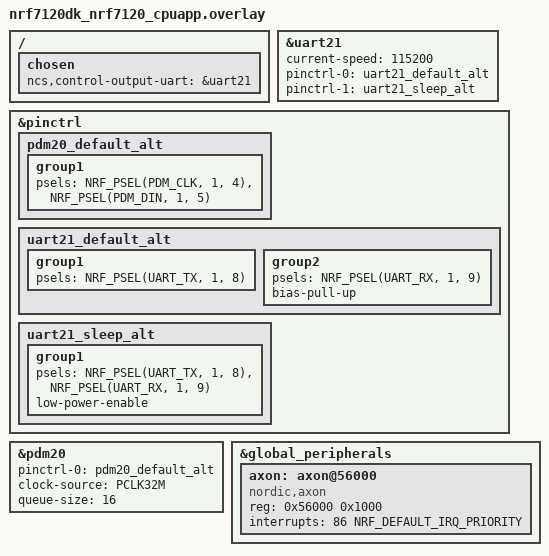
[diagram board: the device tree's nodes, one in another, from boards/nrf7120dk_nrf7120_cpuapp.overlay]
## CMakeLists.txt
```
#
# Copyright (c) 2026 Nordic Semiconductor ASA
#
# SPDX-License-Identifier: LicenseRef-Nordic-5-Clause
#

cmake_minimum_required(VERSION 3.20.0)

find_package(Zephyr REQUIRED HINTS $ENV{ZEPHYR_BASE})
project(ww_kws)

target_sources(app PRIVATE
  src/main.c

  src/control_output.c
  src/dmic.c
  src/leds.c

  src/ww/wakeword.c
  src/ww/nrf_edgeai_generated/nrf_edgeai_user_model.c

  src/kws/kws.c
  src/kws/nrf_edgeai_generated/nrf_edgeai_user_model.c
)

target_sources_ifdef(CONFIG_MODELS_OBSERVABILITY_WW app PRIVATE src/ww/ww_obsv.c)
target_sources_ifdef(CONFIG_MODELS_OBSERVABILITY_KWS app PRIVATE src/kws/kws_obsv.c)
target_sources_ifdef(CONFIG_MODELS_OBSERVABILITY_MDS app PRIVATE src/ble/ble_mds.c)
target_sources_ifdef(CONFIG_MODELS_OBSERVABILITY_MEMFAULT_HTTP app PRIVATE src/wifi/memfault_http_obsv.c)

if(CONFIG_WIFI_NRF71_PATCH)
  # Without the patch regions in the devicetree, the Wi-Fi ROM patches are
  # silently left out of the image and the Wi-Fi core never starts.
  dt_nodelabel(umac_patch NODELABEL umac_rom_patch_addr)
  if(NOT umac_patch)
    message(FATAL_ERROR
      "The Wi-Fi transport needs the Wi-Fi ROM patch regions. "
      "Add -DEXTRA_DTC_OVERLAY_FILE=observability_wifi.overlay")
  endif()

  # Place the Axon models above the Wi-Fi ROM patches, page aligned.
  dt_reg_addr(umac_patch_addr PATH ${umac_patch})
  dt_reg_size(umac_patch_size PATH ${umac_patch})
  math(EXPR AXON_MODELS_ADDR
    "((${umac_patch_addr} + ${umac_patch_size} + 0xFFF) / 0x1000) * 0x1000"
    OUTPUT_FORMAT HEXADECIMAL)
  configure_file(axon_models_after_wifi_patch.ld.in
    ${CMAKE_CURRENT_BINARY_DIR}/axon_models_after_wifi_patch.ld @ONLY)
  zephyr_linker_sources(ROM_SECTIONS
    ${CMAKE_CURRENT_BINARY_DIR}/axon_models_after_wifi_patch.ld)
endif()
```

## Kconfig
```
#
# Copyright (c) 2026 Nordic Semiconductor ASA
#
# SPDX-License-Identifier: LicenseRef-Nordic-5-Clause
#

menu "Wakeword and Keyword Spotting application"

choice APP_MODE
	prompt "Application mode"
	default APP_MODE_WW_GATED_KWS

config APP_MODE_WW_GATED_KWS
	bool "Wakeword-gated keyword spotting mode"
	help
	  Run keyword spotting model only after wakeword was detected. After configurable duration
	  without any keyword spotted switch back to wakeword detection.

config APP_MODE_WW_ONLY
	bool "Wakeword detection only mode"
	help
	  Run wakeword detection continuously without switching to keyword spotting.

config APP_MODE_KWS_ONLY
	bool "Keyword spotting only mode"
	help
	  Run keyword spotting continuously without the need to detect wakeword first.

endchoice

config WW_PROBABILITY_THRESHOLD
	int "Wakeword probability threshold"
	range 0 1000
	default 990
	help
	   Probability threshold for wakeword detection model. The value is expressed in units of
	   1/1000.

config WW_HISTORY_SIZE
	int "Size of wakeword predictions history"
	range 1 32
	default 20
	help
	  Size of history of previous results from wakeword detection model. Each entry corresponds
	  to 30 milliseconds of past audio.

config WW_COUNT_THRESHOLD
	int "Threshold for wakeword detection from predictions history"
	range 1 WW_HISTORY_SIZE
	default 15
	help
	  Number of predictions above threshold in predictions history required to confirm wakeword
	  detection.

config KWS_PERIOD_MS
	int "Length of keyword spotting window in wakeword-gated mode"
	default 3000

config KWS_EMA_ALPHA
	int "Exponential moving average coefficient for class probability"
	range 0 1000
	default 120
	help
	  Coefficient for new entries in exponential moving average calculation for average class
	  probability. The value is expressed in units of 1/1000.

config MODELS_OBSERVABILITY_WW
	bool "Edge AI observability for the wakeword model"
	depends on NRF_EDGEAI_OBSV
	depends on NRF_EDGEAI_OBSV_MEMFAULT
	depends on APP_MODE_WW_GATED_KWS || APP_MODE_WW_ONLY
	help
	  Collect observability metrics for the wakeword model. Its single output is expanded into
	  a synthetic 2-class [1 - p, p] distribution so the probability metrics apply to it.

config MODELS_OBSERVABILITY_KWS
	bool "Edge AI observability for the keyword spotting model"
	depends on NRF_EDGEAI_OBSV
	depends on NRF_EDGEAI_OBSV_MEMFAULT
	depends on APP_MODE_WW_GATED_KWS || APP_MODE_KWS_ONLY
	depends on NRF_EDGEAI_OBSV_MEMFAULT_MAX_CONTEXTS >= 2 || !MODELS_OBSERVABILITY_WW
	help
	  Collect observability metrics for the keyword spotting model. Enabling it together with
	  MODELS_OBSERVABILITY_WW (wakeword-gated mode runs both models) registers two Memfault
	  contexts, so NRF_EDGEAI_OBSV_MEMFAULT_MAX_CONTEXTS must be >= 2.

config MODELS_OBSERVABILITY
	def_bool MODELS_OBSERVABILITY_WW || MODELS_OBSERVABILITY_KWS
	help
	  Auto-selected umbrella: set when observability is enabled for at least one model. Each model
	  has its own observability file (src/ww/ww_obsv.c, src/kws/kws_obsv.c) gated by its own
	  option; this symbol only gates what is shared, such as the Memfault Diagnostic Service.

config MODELS_OBSERVABILITY_MDS
	def_bool y
	depends on MODELS_OBSERVABILITY
	depends on BT_MDS
	depends on BT_SMP
	depends on NRF_EDGEAI_OBSV_MEMFAULT_AUTO_COLLECT

config MODELS_OBSERVABILITY_MEMFAULT_HTTP
	def_bool y
	depends on MODELS_OBSERVABILITY
	depends on MEMFAULT_HTTP_ENABLE
	depends on MEMFAULT_PERIODIC_UPLOAD
	depends on NET_CONNECTION_MANAGER
	depends on NRF_EDGEAI_OBSV_MEMFAULT_AUTO_COLLECT
	help
	  Keep a network (for example Wi-Fi) connection up, and let the Memfault SDK upload the
	  observability data directly to Memfault over HTTPS.

endmenu

source "Kconfig.zephyr"
```

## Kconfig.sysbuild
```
#
# Copyright (c) 2026 Nordic Semiconductor
#
# SPDX-License-Identifier: LicenseRef-Nordic-5-Clause
#

config APP_MODEL_OTA
	bool "Load wakeword/keyword-spotting models from separate flash partitions (model-only OTA)"
	default n
	depends on BOOTLOADER_MCUBOOT
	help
	  When enabled, the application loads wakeword and keyword-spotting models from
	  dedicated flash partitions (model-only OTA). Propagated to the ww_kws image as
	  CONFIG_APP_MODEL_OTA.

source "share/sysbuild/Kconfig"
```

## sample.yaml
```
sample:
  description: Wakeword and Keyword Spotting application
  name: ww kws

common:
  sysbuild: true
  build_only: true
  tags:
    - ci_build
    - sysbuild
    - ci_applications_ww_kws
  harness: console
  harness_config:
    type: multi_line
    regex:
      - "Initialization completed"


tests:
  applications.ww_kws.zdebug:
    platform_allow:
      - nrf54lm20dk/nrf54lm20b/cpuapp
      - nrf7120dk/nrf7120e/cpuapp
    integration_platforms:
      - nrf54lm20dk/nrf54lm20b/cpuapp
      - nrf7120dk/nrf7120e/cpuapp

  applications.ww_kws.zrelease:
    extra_args:
      - FILE_SUFFIX=release
    platform_allow:
      - nrf54lm20dk/nrf54lm20b/cpuapp
      - nrf7120dk/nrf7120e/cpuapp
    integration_platforms:
      - nrf54lm20dk/nrf54lm20b/cpuapp
      - nrf7120dk/nrf7120e/cpuapp

  applications.ww_kws.obsv_ble.zdebug:
    extra_args:
      - EXTRA_CONF_FILE="observability.conf;observability_ble.conf"
    platform_allow:
      - nrf54lm20dk/nrf54lm20b/cpuapp
      - nrf7120dk/nrf7120e/cpuapp
    integration_platforms:
      - nrf54lm20dk/nrf54lm20b/cpuapp
      - nrf7120dk/nrf7120e/cpuapp

  applications.ww_kws.obsv_ble.zrelease:
    extra_args:
      - FILE_SUFFIX=release
      - EXTRA_CONF_FILE="observability.conf;observability_ble.conf"
    platform_allow:
      - nrf54lm20dk/nrf54lm20b/cpuapp
      - nrf7120dk/nrf7120e/cpuapp
    integration_platforms:
      - nrf54lm20dk/nrf54lm20b/cpuapp
      - nrf7120dk/nrf7120e/cpuapp

  applications.ww_kws.obsv_wifi.zdebug:
    extra_args:
      - EXTRA_CONF_FILE="observability.conf;observability_wifi.conf"
      - EXTRA_DTC_OVERLAY_FILE="observability_wifi.overlay"
    platform_allow:
      - nrf7120dk/nrf7120e/cpuapp
    integration_platforms:
      - nrf7120dk/nrf7120e/cpuapp

  applications.ww_kws.obsv_wifi.zrelease:
    extra_args:
      - FILE_SUFFIX=release
      - EXTRA_CONF_FILE="observability.conf;observability_wifi.conf"
      - EXTRA_DTC_OVERLAY_FILE="observability_wifi.overlay"
    platform_allow:
      - nrf7120dk/nrf7120e/cpuapp
    integration_platforms:
      - nrf7120dk/nrf7120e/cpuapp
```

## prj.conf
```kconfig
#
# Copyright (c) 2026 Nordic Semiconductor
#
# SPDX-License-Identifier: LicenseRef-Nordic-5-Clause
#

# nRF Edge AI
CONFIG_NRF_EDGEAI=y

# nRF Edge AI dependencies
CONFIG_NRF_AXON=y
CONFIG_FPU=y

# Size of interlayer buffer to fit model
CONFIG_NRF_AXON_INTERLAYER_BUFFER_SIZE=6656

# Size of psum buffer to fit model
CONFIG_NRF_AXON_PSUM_BUFFER_SIZE=0

# Enable sensor, button and LED libraries
CONFIG_GPIO=y
CONFIG_AUDIO=y
CONFIG_AUDIO_DMIC=y

# Enable logging and assert
CONFIG_LOG=y
CONFIG_CONSOLE=y
CONFIG_SERIAL=y
CONFIG_ASSERT=y

CONFIG_UART_ASYNC_API=y

CONFIG_NCS_SAMPLES_DEFAULTS=y

CONFIG_BOOTLOADER_MCUBOOT=y

# Flash + CRC (required by MCUMGR image DFU and UART transport)
CONFIG_FLASH=y
CONFIG_FLASH_MAP=y
CONFIG_CRC=y

# FW and model DFU over SMP (UART)
CONFIG_NET_BUF=y
CONFIG_ZCBOR=y
CONFIG_BASE64=y
CONFIG_STREAM_FLASH=y
CONFIG_MCUMGR=y
CONFIG_MCUMGR_MGMT_NOTIFICATION_HOOKS=y
CONFIG_UART_MCUMGR=y
CONFIG_MCUMGR_TRANSPORT_UART=y
CONFIG_IMG_MANAGER=y
CONFIG_MCUMGR_GRP_IMG=y
CONFIG_MCUMGR_GRP_IMG_STATUS_HOOKS=y
CONFIG_MCUMGR_GRP_IMG_UPLOAD_CHECK_HOOK=y
CONFIG_MCUMGR_GRP_OS=y
CONFIG_SYSTEM_WORKQUEUE_STACK_SIZE=4096

# control_output uses async TX on uart30; MCUMGR selects interrupt-driven globally.
CONFIG_UART_30_ASYNC=y
CONFIG_UART_30_INTERRUPT_DRIVEN=n
```

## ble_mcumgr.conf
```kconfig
#
# Copyright (c) 2026 Nordic Semiconductor ASA
#
# SPDX-License-Identifier: LicenseRef-Nordic-5-Clause
#
# SMP over Bluetooth for nRF Connect Device Manager manual image upload.

CONFIG_BT=y
CONFIG_BT_SMP=y
CONFIG_BT_PERIPHERAL=y
CONFIG_BT_DEVICE_NAME="WW KWS"
CONFIG_BT_PRIVACY=y

CONFIG_BT_BUF_ACL_RX_SIZE=251
CONFIG_BT_L2CAP_TX_MTU=247
CONFIG_BT_BUF_ACL_TX_SIZE=251
CONFIG_BT_CTLR_DATA_LENGTH_MAX=251

CONFIG_SETTINGS=y
CONFIG_ZMS=y
CONFIG_BT_SETTINGS=y

CONFIG_MCUMGR_GRP_OS_BOOTLOADER_INFO=y
CONFIG_MCUMGR_TRANSPORT_BT=y
CONFIG_MCUMGR_TRANSPORT_BT_CONN_PARAM_CONTROL=y
CONFIG_MCUMGR_TRANSPORT_BT_REASSEMBLY=y
# BT_SMP defaults SMP GATT to authenticated; Device Manager needs open access.
CONFIG_MCUMGR_TRANSPORT_BT_PERM_RW=y
CONFIG_MCUMGR_TRANSPORT_NETBUF_SIZE=1220
CONFIG_MCUMGR_GRP_OS_MCUMGR_PARAMS=y
CONFIG_MCUMGR_TRANSPORT_WORKQUEUE_STACK_SIZE=4608
```

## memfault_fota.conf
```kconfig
#
# Copyright (c) 2026 Nordic Semiconductor ASA
#
# SPDX-License-Identifier: LicenseRef-Nordic-5-Clause
#
# Memfault release-management OTA via nRF Connect Device Manager.
# Compose with observability.conf for MDS observability on the same BLE link.
# Replaces ble_mcumgr.conf when Memfault-managed application FOTA is required.

CONFIG_WW_KWS_MEMFAULT_FOTA=y

CONFIG_BT=y
CONFIG_BT_SMP=y
CONFIG_BT_PERIPHERAL=y
CONFIG_BT_DEVICE_NAME="WW KWS"
CONFIG_BT_PRIVACY=y

CONFIG_BT_BUF_ACL_RX_SIZE=251
CONFIG_BT_L2CAP_TX_MTU=247
CONFIG_BT_BUF_ACL_TX_SIZE=251
CONFIG_BT_CTLR_DATA_LENGTH_MAX=251

CONFIG_SETTINGS=y
CONFIG_ZMS=y
CONFIG_BT_SETTINGS=y

CONFIG_MEMFAULT=y
CONFIG_MEMFAULT_USER_CONFIG_ENABLE=n
CONFIG_MEMFAULT_PROJECT_KEY=""

CONFIG_NCS_SAMPLE_MCUMGR_BT_OTA_DFU=y
CONFIG_MCUMGR_GRP_OS_INFO=y
CONFIG_MCUMGR_TRANSPORT_WORKQUEUE_STACK_SIZE=4608

# Device Information Service required by Device Manager Memfault FOTA.
CONFIG_BT_DIS=y
CONFIG_BT_DIS_SERIAL_NUMBER=y
CONFIG_BT_DIS_HW_REV=y
CONFIG_BT_DIS_SW_REV=y
CONFIG_BT_DIS_FW_REV=y
CONFIG_BT_DIS_SETTINGS=y
CONFIG_SETTINGS_RUNTIME=y

# Align the Memfault and DIS device serial numbers with the SoC unique ID.
CONFIG_HW_ID_LIBRARY=y
CONFIG_HW_ID_LIBRARY_SOURCE_DEVICE_ID=y
# CONFIG_MEMFAULT_NCS_DEVICE_ID_STATIC is not set
CONFIG_MEMFAULT_NCS_DEVICE_ID_HW_ID=y

# Static firmware version from VERSION through the Kconfig defaults.
CONFIG_MEMFAULT_NCS_FW_VERSION_STATIC=y
CONFIG_MEMFAULT_NCS_HW_VERSION="nrf54lm20dk-kws-fota"

# Set CONFIG_MEMFAULT_PROJECT_KEY in memfault_user.conf.
```

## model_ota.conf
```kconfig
#
# Copyright (c) 2026 Nordic Semiconductor ASA
#
# SPDX-License-Identifier: LicenseRef-Nordic-5-Clause
#
# Application options for partition-resident models (model-only OTA).

# Device Manager CONFIRM_ONLY confirms model images by hash even though they
# occupy non-active, in-place primary slots.
CONFIG_MCUMGR_GRP_IMG_ALLOW_CONFIRM_NON_ACTIVE_IMAGE_ANY=y
```

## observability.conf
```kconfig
#
# Copyright (c) 2026 Nordic Semiconductor
#
# SPDX-License-Identifier: LicenseRef-Nordic-5-Clause
#

# Enable observability
CONFIG_NRF_EDGEAI_OBSV=y
CONFIG_NRF_EDGEAI_OBSV_ENCODE=y

# Enable observability for both models in the default wakeword-gated mode
CONFIG_MODELS_OBSERVABILITY_WW=y
CONFIG_MODELS_OBSERVABILITY_KWS=y

# Resource sizing for: KWS has 12 classes, WW uses 2 synthetic classes,
# and both produce 40 mel features. The workqueue stack includes
# space for encoding both contexts plus headroom.
CONFIG_NRF_EDGEAI_OBSV_MAX_CLASSES=12
CONFIG_NRF_EDGEAI_OBSV_MEMFAULT_MAX_CONTEXTS=2
CONFIG_SYSTEM_WORKQUEUE_STACK_SIZE=12288

# All built-in metrics, applied to both models
CONFIG_NRF_EDGEAI_OBSV_METRIC_CLASS_PRED_DIST=y
CONFIG_NRF_EDGEAI_OBSV_CLASS_PRED_DIST_BIN_NUM=16
CONFIG_NRF_EDGEAI_OBSV_CLASS_PRED_DIST_STREAK_TOP_BIN=30
CONFIG_NRF_EDGEAI_OBSV_CLASS_PRED_DIST_STREAK_TOL=1
CONFIG_NRF_EDGEAI_OBSV_METRIC_TRANSITION_MATRIX=y
CONFIG_NRF_EDGEAI_OBSV_METRIC_MODEL_CERTAINTY_DESC=y
CONFIG_NRF_EDGEAI_OBSV_MODEL_CERTAINTY_DESC_BIN_NUM=16
CONFIG_NRF_EDGEAI_OBSV_METRIC_MEL_ENERGY_DESC=y
CONFIG_NRF_EDGEAI_OBSV_MEL_ENERGY_DESC_BIN_NUM=16
CONFIG_NRF_EDGEAI_OBSV_MEL_ENERGY_DESC_MAX_FEATURES=40
CONFIG_NRF_EDGEAI_OBSV_MEL_ENERGY_DESC_SCALE_P01_MILLI=0
CONFIG_NRF_EDGEAI_OBSV_MEL_ENERGY_DESC_SCALE_P99_MILLI=16000
CONFIG_NRF_EDGEAI_OBSV_METRIC_MEL_SPECTRAL_DESC=y
CONFIG_NRF_EDGEAI_OBSV_MEL_SPECTRAL_DESC_BIN_NUM=16

# Enable Memfault observability and auto collect
CONFIG_NRF_EDGEAI_OBSV_MEMFAULT=y
CONFIG_NRF_EDGEAI_OBSV_MEMFAULT_AUTO_COLLECT=y
CONFIG_ZCBOR=y

# Memfault settings
CONFIG_MEMFAULT=y
CONFIG_MEMFAULT_USER_CONFIG_ENABLE=n

# This file selects no transport. Combine it with one transport file:
#   observability_ble.conf  - Bluetooth LE with the Memfault Diagnostic Service
#   observability_wifi.conf - Wi-Fi with direct Memfault upload over HTTPS
```

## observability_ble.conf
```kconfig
#
# Copyright (c) 2026 Nordic Semiconductor
#
# SPDX-License-Identifier: LicenseRef-Nordic-5-Clause
#

# Bluetooth LE transport for observability.
# Use together with observability.conf:
#   -DEXTRA_CONF_FILE="observability.conf;observability_ble.conf"
#
# Metrics are drained by a gateway (phone or web browser) that connects over
# the Memfault Diagnostic Service and forwards the chunks to Memfault.

# Memfault project and device identification, sent to the gateway over MDS
CONFIG_MEMFAULT_NCS_PROJECT_KEY=""
CONFIG_MEMFAULT_NCS_DEVICE_ID_STATIC=y
CONFIG_MEMFAULT_NCS_DEVICE_ID="ww-kws-obsv"

# Bluetooth MDS
CONFIG_BT=y
CONFIG_BT_SMP=y
CONFIG_BT_PERIPHERAL=y
CONFIG_BT_DEVICE_NAME="WW KWS Obsv"
CONFIG_BT_PRIVACY=y
CONFIG_BT_MDS=y

CONFIG_BT_BUF_ACL_RX_SIZE=251
CONFIG_BT_L2CAP_TX_MTU=247
CONFIG_BT_BUF_ACL_TX_SIZE=251
CONFIG_BT_CTLR_DATA_LENGTH_MAX=251

# Enable bonding
CONFIG_SETTINGS=y
CONFIG_ZMS=y
CONFIG_BT_SETTINGS=y
CONFIG_FLASH=y
CONFIG_FLASH_PAGE_LAYOUT=y
CONFIG_FLASH_MAP=y
```

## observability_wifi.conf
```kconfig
#
# Copyright (c) 2026 Nordic Semiconductor
#
# SPDX-License-Identifier: LicenseRef-Nordic-5-Clause
#

# Wi-Fi transport for observability on the nRF7120 DK, uploading directly to
# Memfault over HTTPS. Use together with observability.conf:
#   -DEXTRA_CONF_FILE="observability.conf;observability_wifi.conf"
#   -DEXTRA_DTC_OVERLAY_FILE=observability_wifi.overlay
#
# The device connects to a Wi-Fi access point and the Memfault SDK posts its data
# (including the observability CDR) to the Memfault cloud. Only the Memfault
# project key (below) and the Wi-Fi credentials (shell, wifi cred add) are needed.
#
# Based on the nRF Connect SDK Memfault sample (samples/debug/memfault,
# prj.conf + boards/nrf7002dk_nrf5340_cpuapp.conf).

# Memfault project key, from Project -> Settings -> General in the Memfault app
CONFIG_MEMFAULT_PROJECT_KEY=""

# nRF7120 Wi-Fi ROM patches
CONFIG_WIFI_NRF71_PATCH=y

# Memory
CONFIG_HEAP_MEM_POOL_SIZE=40144
CONFIG_HEAP_MEM_POOL_IGNORE_MIN=y
CONFIG_NRF_WIFI_CTRL_HEAP_SIZE=20000
CONFIG_NRF_WIFI_DATA_HEAP_SIZE=92856
# As in the Memfault sample
CONFIG_MAIN_STACK_SIZE=8192

# Networking
CONFIG_NETWORKING=y
CONFIG_NET_NATIVE=y
CONFIG_NET_SOCKETS=y
CONFIG_NET_SOCKETS_OFFLOAD=n
CONFIG_NET_L2_ETHERNET=y
CONFIG_NET_IPV4=y
CONFIG_NET_IPV6=y
CONFIG_NET_IPV6_NBR_CACHE=n
CONFIG_NET_IPV6_MLD=n
CONFIG_NET_TCP=y
CONFIG_NET_DHCPV4=y
CONFIG_NET_CONTEXT_SNDTIMEO=y
CONFIG_NET_CONTEXT_SYNC_RECV=y
CONFIG_NET_MAX_CONN=8
CONFIG_NET_MAX_CONTEXTS=8
CONFIG_NET_MGMT_EVENT_QUEUE_SIZE=30
CONFIG_NET_MGMT_EVENT_STACK_SIZE=8192
CONFIG_NET_TX_STACK_SIZE=2048
CONFIG_NET_RX_STACK_SIZE=2048
CONFIG_ZVFS_POLL_MAX=8
CONFIG_POSIX_API=y
CONFIG_DNS_RESOLVER=y
CONFIG_NET_SOCKETS_DNS_TIMEOUT=30000

# Connection manager: brings the Wi-Fi interface up and connects using stored credentials
CONFIG_NET_CONNECTION_MANAGER=y
CONFIG_NET_CONNECTION_MANAGER_MONITOR_STACK_SIZE=6144

# Wi-Fi station
CONFIG_WIFI=y
CONFIG_WIFI_NM_WPA_SUPPLICANT=y
CONFIG_WIFI_NM_WPA_SUPPLICANT_THREAD_STACK_SIZE=6144
CONFIG_L2_WIFI_CONNECTIVITY=y
CONFIG_WIFI_CREDENTIALS=y

# TLS for HTTPS to Memfault. The Memfault integration installs its root certificates
# at every boot, so they are kept in the default volatile TLS credentials backend.
CONFIG_NET_SOCKETS_SOCKOPT_TLS=y
CONFIG_NET_SOCKETS_TLS_MAX_CONTEXTS=2
CONFIG_TLS_CREDENTIALS=y

# mbedTLS, as in the Memfault sample
CONFIG_PSA_CRYPTO=y
CONFIG_MBEDTLS=y
CONFIG_MBEDTLS_ENABLE_HEAP=y
CONFIG_MBEDTLS_HEAP_SIZE=81920

CONFIG_PSA_WANT_ALG_RSA_PKCS1V15_CRYPT=y
CONFIG_PSA_WANT_ALG_RSA_PKCS1V15_SIGN=y
CONFIG_PSA_WANT_ALG_RSA_PSS=y
CONFIG_PSA_WANT_ALG_RSA_OAEP=y
CONFIG_PSA_WANT_RSA_KEY_SIZE_2048=y
CONFIG_PSA_WANT_KEY_TYPE_RSA_KEY_PAIR_IMPORT=y
CONFIG_PSA_WANT_KEY_TYPE_RSA_KEY_PAIR_EXPORT=y
CONFIG_PSA_WANT_KEY_TYPE_RSA_KEY_PAIR_DERIVE=y
CONFIG_PSA_WANT_KEY_TYPE_RSA_KEY_PAIR_GENERATE=y

CONFIG_MBEDTLS_SSL_SERVER_NAME_INDICATION=y
CONFIG_MBEDTLS_X509_CRT_PARSE_C=y

# Not in the sample: the ECDHE-RSA key exchange used by the Memfault servers is only enabled
# by default when ECDH is available. Without it only PSK ciphersuites are offered and the
# handshake is closed by the server. The ephemeral ECDH key also needs the ECC key pair
# types, or the client key exchange fails with MBEDTLS_ERR_SSL_HW_ACCEL_FAILED.
CONFIG_PSA_WANT_ALG_ECDH=y
CONFIG_PSA_WANT_KEY_TYPE_ECC_KEY_PAIR_IMPORT=y
CONFIG_PSA_WANT_KEY_TYPE_ECC_KEY_PAIR_EXPORT=y
CONFIG_PSA_WANT_KEY_TYPE_ECC_KEY_PAIR_GENERATE=y

# Memfault over HTTPS
CONFIG_MEMFAULT_HTTP_ENABLE=y
CONFIG_MEMFAULT_ROOT_CERT_STORAGE_TLS_CREDENTIAL_STORAGE=y
CONFIG_MEMFAULT_NCS_PROVISION_CERTIFICATES=y
# Memfault device ID from the SoC device ID (same value nRF Cloud would use)
CONFIG_MEMFAULT_NCS_DEVICE_ID_HW_ID=y
CONFIG_HW_ID_LIBRARY_SOURCE_DEVICE_ID=y
CONFIG_MEMFAULT_PERIODIC_UPLOAD=y
CONFIG_MEMFAULT_PERIODIC_UPLOAD_USE_DEDICATED_WORKQUEUE=y
CONFIG_MEMFAULT_PERIODIC_UPLOAD_DEDICATED_WORKQUEUE_STACK_SIZE=8192
# Started by the application once the network is connected
CONFIG_MEMFAULT_PERIODIC_UPLOAD_ENABLED_DEFAULT=n
# Telemetry only: no Memfault OTA, and no Memfault shell (its OTA command needs it)
CONFIG_MEMFAULT_ZEPHYR_FOTA=n
CONFIG_MEMFAULT_SHELL=n
# Logs are not uploaded. Memfault log capture would also force CONFIG_LOG on in release builds.
CONFIG_MEMFAULT_LOGGING_ENABLE=n

# Persistent storage for Wi-Fi credentials
CONFIG_SETTINGS=y
CONFIG_ZMS=y
CONFIG_FLASH=y
CONFIG_FLASH_PAGE_LAYOUT=y
CONFIG_FLASH_MAP=y

# Shell for provisioning Wi-Fi credentials.
# Also enabled on top of the release configuration, as provisioning needs it.
CONFIG_SHELL=y
CONFIG_SHELL_STACK_SIZE=6144
CONFIG_NET_L2_WIFI_SHELL=y
CONFIG_WIFI_CREDENTIALS_SHELL=y
# The shell enables the interrupt-driven UART API, which takes UART21 away
# from the async API that the control output uses.
CONFIG_UART_21_INTERRUPT_DRIVEN=n
```

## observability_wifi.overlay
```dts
/*
 * Copyright (c) 2026 Nordic Semiconductor ASA
 *
 * SPDX-License-Identifier: LicenseRef-Nordic-5-Clause
 */

/* Wi-Fi ROM patch regions, required with observability_wifi.conf on the nRF7120 DK. */
#include <vendor/nordic/wifi/nrf7120_wifi_patch_0_1_0.dtsi>

/* Wi-Fi connection setup can stall the audio path for longer than the default four blocks
 * (about 120 ms), so give the DMIC more buffering when Wi-Fi is enabled.
 */
&dmic_dev {
	queue-size = <16>;
};
```

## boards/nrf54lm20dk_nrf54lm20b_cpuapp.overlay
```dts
/*
 * Copyright (c) 2026 Nordic Semiconductor ASA
 *
 * SPDX-License-Identifier: LicenseRef-Nordic-5-Clause
 */

#include "../dts/nrf54lm20dk_mcuboot_model.dtsi"

/ {
	chosen {
		ncs,control-output-uart = &uart30;
	};
};

&uart30 {
	status = "okay";
};

&pinctrl {
	pdm20_default_alt: pdm20_default_alt {
		group1 {
			psels = <NRF_PSEL(PDM_CLK, 1, 4)>,
				<NRF_PSEL(PDM_DIN, 1, 5)>;
		};
	};
};

dmic_dev: &pdm20 {
	status = "okay";
	pinctrl-0 = <&pdm20_default_alt>;
	pinctrl-names = "default";
	clock-source = "PCLK32M";
};

&axon {
	status = "okay";
};
```

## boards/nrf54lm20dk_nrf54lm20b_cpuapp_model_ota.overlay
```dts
/*
 * Copyright (c) 2026 Nordic Semiconductor ASA
 *
 * SPDX-License-Identifier: LicenseRef-Nordic-5-Clause
 *
 * Three-image MCUboot layout (FW + WW/KWS model partitions).
 * Applied from sysbuild.cmake when SB_CONFIG_APP_MODEL_OTA is enabled.
 */

#include "../dts/nrf54lm20dk_mcuboot_model_ota.dtsi"
```

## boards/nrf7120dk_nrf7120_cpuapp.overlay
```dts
/*
 * Copyright (c) 2026 Nordic Semiconductor ASA
 *
 * SPDX-License-Identifier: LicenseRef-Nordic-5-Clause
 */

/ {
	chosen {
		ncs,control-output-uart = &uart21;
	};
};

&uart21 {
	status = "okay";
	current-speed = <115200>;
	pinctrl-0 = <&uart21_default_alt>;
	pinctrl-1 = <&uart21_sleep_alt>;
	pinctrl-names = "default", "sleep";
};

&pinctrl {
	pdm20_default_alt: pdm20_default_alt {
		group1 {
			psels = <NRF_PSEL(PDM_CLK, 1, 4)>,
				<NRF_PSEL(PDM_DIN, 1, 5)>;
		};
	};

	uart21_default_alt: uart21_default_alt {
		group1 {
			psels = <NRF_PSEL(UART_TX, 1, 8)>;
		};

		group2 {
			psels = <NRF_PSEL(UART_RX, 1, 9)>;
			bias-pull-up;
		};
	};

	uart21_sleep_alt: uart21_sleep_alt {
		group1 {
			psels = <NRF_PSEL(UART_TX, 1, 8)>,
				<NRF_PSEL(UART_RX, 1, 9)>;
			low-power-enable;
		};
	};
};

dmic_dev: &pdm20 {
	status = "okay";
	pinctrl-0 = <&pdm20_default_alt>;
	pinctrl-names = "default";
	clock-source = "PCLK32M";
	queue-size = <16>;
};

&global_peripherals {
	axon: axon@56000 {
		compatible = "nordic,axon";
		reg = <0x56000 0x1000>;
		interrupts = <86 NRF_DEFAULT_IRQ_PRIORITY>;
		status = "okay";
	};
};
```

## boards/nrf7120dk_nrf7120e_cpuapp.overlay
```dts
/*
 * Copyright (c) 2026 Nordic Semiconductor ASA
 *
 * SPDX-License-Identifier: LicenseRef-Nordic-5-Clause
 */

/*
 * Control output goes to UART21, which the board routes to the onboard debugger
 * (TX P1.08, RX P1.09). Pins and baud rate are inherited from the board files.
 */
/ {
	chosen {
		ncs,control-output-uart = &uart21;
	};
};

&uart21 {
	status = "okay";
};

&pinctrl {
	pdm20_default_alt: pdm20_default_alt {
		group1 {
			psels = <NRF_PSEL(PDM_CLK, 1, 4)>,
				<NRF_PSEL(PDM_DIN, 1, 5)>;
		};
	};
};

dmic_dev: &pdm20 {
	status = "okay";
	pinctrl-0 = <&pdm20_default_alt>;
	pinctrl-names = "default";
	clock-source = "PCLK32M";
};

&axon {
	status = "okay";
};
```

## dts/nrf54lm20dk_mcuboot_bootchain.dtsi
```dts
/*
 * Copyright (c) 2026 Nordic Semiconductor ASA
 *
 * SPDX-License-Identifier: LicenseRef-Nordic-5-Clause
 *
 * MCUboot bootchain for ww_kws (image 0 = app, image 1 = WW model, image 2 = KWS model).
 */

/ {
	bootchain {
		b0_mcuboot {
			compatible = "nordic,mcuboot";
			uuid-vid-required;
			uuid-cid-required;
			partitions = <&boot_partition>;

			images {
				application {
					compatible = "nordic,mcuboot-image";
					image-index = <0>;
					uuid-vid = "nordicsemi.com", "nordicsemi.com";
					uuid-cid = "nRF54LM20_ww_kws_app", "nRF54LM20_ww_kws_app";
					partitions = <&slot0_partition &slot1_partition>;
				};
				ww_model_image {
					compatible = "nordic,mcuboot-image";
					image-index = <1>;
					uuid-vid = "nordicsemi.com", "nordicsemi.com";
					uuid-cid = "nRF54LM20_ww_kws_model_ww", "nRF54LM20_ww_kws_model_ww";
					partitions = <&slot2_partition &slot3_partition>;
				};
				kws_model_image {
					compatible = "nordic,mcuboot-image";
					image-index = <2>;
					uuid-vid = "nordicsemi.com", "nordicsemi.com";
					uuid-cid = "nRF54LM20_ww_kws_model_kws", "nRF54LM20_ww_kws_model_kws";
					partitions = <&slot4_partition &slot5_partition>;
				};
			};
		};
	};
};
```

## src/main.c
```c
/*
 * Copyright (c) 2026 Nordic Semiconductor ASA
 *
 * SPDX-License-Identifier: LicenseRef-Nordic-5-Clause
 */

#include <stddef.h>
#include <stdint.h>

#include <zephyr/audio/dmic.h>
#include <zephyr/device.h>
#include <zephyr/devicetree.h>
#include <zephyr/logging/log.h>

#include "ble/ble_mds.h"
#include "wifi/memfault_http_obsv.h"
#include "control_output.h"
#include "dmic.h"
#include "kws/kws.h"
#include "leds.h"
#include "ww/wakeword.h"

LOG_MODULE_REGISTER(main);

#define DMIC_READ_TIMEOUT 100

static const struct device *const dmic_dev = DEVICE_DT_GET(DT_NODELABEL(dmic_dev));

static int ww_loop(void)
{
	int err;
	void *audio_buffer;
	size_t audio_buffer_size;
	bool ww_detected;

	ww_reset();

	print_control_output((struct control_message){CONTROL_MESSAGE_WAITING_WW});

	while (true) {
		err = dmic_read(dmic_dev, 0, &audio_buffer, &audio_buffer_size, DMIC_READ_TIMEOUT);
		if (err < 0) {
			LOG_ERR("Failed to read from DMIC (err %d)", err);
			return err;
		}

		err = ww_process(audio_buffer, DMIC_SAMPLES_IN_BLOCK, &ww_detected);
		if (err == -EBUSY) {
			/* More data is needed. */
			continue;
		} else if (err < 0) {
			LOG_ERR("Wakeword detection failed (err %d)", err);
			return err;
		}

		if (ww_detected) {
			print_control_output((struct control_message){CONTROL_MESSAGE_WW_DETECTED});
			if (IS_ENABLED(CONFIG_APP_MODE_WW_ONLY)) {
				leds_blink_led0();
			} else {
				return 0;
			}
		}
	}
}

static int kws_loop(void)
{
	int err;
	void *audio_buffer;
	size_t audio_buffer_size;
	struct kws_prediction prediction;

	uint32_t spotting_timeout = k_uptime_get_32() + CONFIG_KWS_PERIOD_MS;

	kws_reset();

	print_control_output((struct control_message){.type = CONTROL_MESSAGE_WAITING_KW});

	while (IS_ENABLED(CONFIG_APP_MODE_KWS_ONLY) || spotting_timeout > k_uptime_get_32()) {
		err = dmic_read(dmic_dev, 0, &audio_buffer, &audio_buffer_size, DMIC_READ_TIMEOUT);
		if (err < 0) {
			LOG_ERR("Failed to read from DMIC (err %d)", err);
			return err;
		}

		err = kws_process(audio_buffer, DMIC_SAMPLES_IN_BLOCK, &prediction);
		if (err == -EBUSY) {
			/* More data is needed. */
			continue;
		} else if (err) {
			LOG_ERR("Keyword spotting failed (err %d)", err);
			return err;
		}

		if (prediction.valid) {
			leds_blink_led1();
			spotting_timeout = k_uptime_get_32() + CONFIG_KWS_PERIOD_MS;
			print_control_output(
				(struct control_message){.type = CONTROL_MESSAGE_KW_SPOTTED,
							 .kw_class = prediction.class,
							 .name = prediction.name});
		}
	}

	print_control_output((struct control_message){.type = CONTROL_MESSAGE_TIMEOUT_KWS});

	return 0;
}

int main(void)
{
	int err;

	err = dmic_init();
	if (err) {
		return err;
	}

	err = leds_init();
	if (err) {
		return err;
	}

	err = control_output_init();
	if (err) {
		return err;
	}

	if (IS_ENABLED(CONFIG_APP_MODE_WW_GATED_KWS) || IS_ENABLED(CONFIG_APP_MODE_WW_ONLY)) {
		err = ww_init();
		if (err) {
			return err;
		}
	}

	if (IS_ENABLED(CONFIG_APP_MODE_WW_GATED_KWS) || IS_ENABLED(CONFIG_APP_MODE_KWS_ONLY)) {
		err = kws_init();
		if (err) {
			return err;
		}
	}

	err = init_app_ble();
	if (err) {
		return err;
	}

	err = init_app_memfault_http();
	if (err) {
		return err;
	}

	LOG_INF("Initialization completed, check output on VCOM0");

	err = dmic_trigger(dmic_dev, DMIC_TRIGGER_START);
	if (err < 0) {
		LOG_ERR("Failed to start DMIC (err %d)", err);
		return err;
	}

	while (true) {
		if (IS_ENABLED(CONFIG_APP_MODE_WW_GATED_KWS) ||
		    IS_ENABLED(CONFIG_APP_MODE_WW_ONLY)) {
			err = ww_loop();
			if (err) {
				return err;
			}
		}

		if (IS_ENABLED(CONFIG_APP_MODE_WW_GATED_KWS)) {
			leds_on_led0();
		}

		if (IS_ENABLED(CONFIG_APP_MODE_WW_GATED_KWS) ||
		    IS_ENABLED(CONFIG_APP_MODE_KWS_ONLY)) {
			err = kws_loop();
			if (err) {
				return err;
			}
		}

		if (IS_ENABLED(CONFIG_APP_MODE_WW_GATED_KWS)) {
			leds_off_led0();
		}
	}

	return 0;
}
```

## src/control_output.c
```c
/*
 * Copyright (c) 2026 Nordic Semiconductor ASA
 *
 * SPDX-License-Identifier: LicenseRef-Nordic-5-Clause
 */

#include <stdalign.h>
#include <stddef.h>
#include <stdio.h>

#include <zephyr/device.h>
#include <zephyr/devicetree.h>
#include <zephyr/drivers/uart.h>
#include <zephyr/kernel.h>
#include <zephyr/logging/log.h>
#include <zephyr/sys/atomic.h>

#include "control_output.h"

LOG_MODULE_REGISTER(control_output);

struct k_work control_output_work;

K_MSGQ_DEFINE(control_msg_queue, sizeof(struct control_message), 10,
	      alignof(struct control_message));

static const char *const messages[] = {
	[CONTROL_MESSAGE_WAITING_WW] = "Waiting for wakeword\r\n",
	[CONTROL_MESSAGE_WW_DETECTED] = "Wakeword detected\r\n",

	[CONTROL_MESSAGE_WAITING_KW] = "Waiting for keywords\r\n",
	[CONTROL_MESSAGE_KW_SPOTTED] = "Keyword spotted: %s\r\n",
	[CONTROL_MESSAGE_TIMEOUT_KWS] = "Keyword spotting window timeout\r\n",
};

BUILD_ASSERT(CONTROL_MESSAGE_COUNT == ARRAY_SIZE(messages),
	     "Mismatch between control_message_type and messages size");

static const struct device *uart_dev = DEVICE_DT_GET(DT_CHOSEN(ncs_control_output_uart));
static atomic_t uart_busy;

static void uart_cb(const struct device *dev, struct uart_event *evt, void *user_data)
{
	int err;

	if (evt->type == UART_TX_DONE) {
		atomic_set(&uart_busy, false);

		if (k_msgq_num_used_get(&control_msg_queue) == 0) {
			return;
		}

		err = k_work_submit(&control_output_work);
		if (err < 0) {
			LOG_ERR("Failed to submit work (err %d)", err);
		}
	}
}

static void control_output_work_handler(struct k_work *work)
{
	int err;
	struct control_message message_item;

	static char output_buffer[40];
	const char *buffer = NULL;
	size_t buffer_len = 0;

	if (atomic_get(&uart_busy)) {
		return;
	}

	/* Peek message to not lose it if uart_tx fails. */
	err = k_msgq_peek(&control_msg_queue, &message_item);
	if (err) {
		return;
	}

	atomic_set(&uart_busy, true);

	switch (message_item.type) {
	case CONTROL_MESSAGE_WAITING_WW:
	case CONTROL_MESSAGE_WW_DETECTED:
	case CONTROL_MESSAGE_WAITING_KW:
	case CONTROL_MESSAGE_TIMEOUT_KWS:
		buffer = messages[message_item.type];
		buffer_len = strlen(buffer);
		break;

	case CONTROL_MESSAGE_KW_SPOTTED: {
		int ret = snprintf(output_buffer, sizeof(output_buffer),
				   messages[message_item.type], message_item.name);

		if (ret < 0) {
			atomic_set(&uart_busy, false);
			k_msgq_get(&control_msg_queue, &message_item, K_NO_WAIT);
			LOG_ERR("snprintf failed (%d)", ret);
			return;
		}
		buffer = output_buffer;
		buffer_len = MIN((size_t)ret, sizeof(output_buffer) - 1);
		break;
	}
	default:
		atomic_set(&uart_busy, false);
		k_msgq_get(&control_msg_queue, &message_item, K_NO_WAIT);
		LOG_WRN("Unhandled case");
		return;
	}

	err = uart_tx(uart_dev, buffer, buffer_len, 0);
	if (err) {
		atomic_set(&uart_busy, false);
		LOG_ERR("Failed to transmit data (err %d)", err);
		return;
	}

	k_msgq_get(&control_msg_queue, &message_item, K_NO_WAIT);
}

int control_output_init(void)
{
	int err;

	if (!device_is_ready(uart_dev)) {
		LOG_ERR("Device is not ready");
		return -ENODEV;
	}

	err = uart_callback_set(uart_dev, uart_cb, NULL);
	if (err) {
		LOG_ERR("Failed to set UART callback (err %d)", err);
	}

	k_work_init(&control_output_work, control_output_work_handler);

	return err;
}

void print_control_output(const struct control_message message)
{
	int err;

	err = k_msgq_put(&control_msg_queue, &message, K_NO_WAIT);
	if (err) {
		LOG_ERR("Failed to put message in queue (err %d)", err);
		return;
	}

	err = k_work_submit(&control_output_work);
	if (err < 0) {
		LOG_ERR("Failed to submit work (err %d)", err);
	}
}
```

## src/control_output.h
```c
/*
 * Copyright (c) 2026 Nordic Semiconductor ASA
 *
 * SPDX-License-Identifier: LicenseRef-Nordic-5-Clause
 */

/**
 * @defgroup control_output Printing control output functions
 * @{
 * @ingroup ww_kws
 */

#ifndef __CONTROL_OUTPUT_H__
#define __CONTROL_OUTPUT_H__

#ifdef __cplusplus
extern "C" {
#endif /* __cplusplus */

/**
 * @brief Control message type.
 */
enum control_message_type {
	CONTROL_MESSAGE_WAITING_WW,
	CONTROL_MESSAGE_WW_DETECTED,
};

/**
 * @brief Control message.
 */
struct control_message {
	enum control_message_type type;
};

/**
 * @brief Initialize control output backend.
 *
 * @return Operation status, 0 for success.
 */
int control_output_init(void);

/**
 * @brief Print the control messages to @c ncs_control_output_uart serial.
 *
 * @param message Control message to be printed.
 */
void print_control_output(const struct control_message message);

#ifdef __cplusplus
}
#endif /* __cplusplus */

#endif /* __CONTROL_OUTPUT_H__ */

/**
 * @}
 */
```

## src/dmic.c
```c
/*
 * Copyright (c) 2026 Nordic Semiconductor ASA
 *
 * SPDX-License-Identifier: LicenseRef-Nordic-5-Clause
 */

#include <stddef.h>

#include <zephyr/audio/dmic.h>
#include <zephyr/device.h>
#include <zephyr/devicetree.h>
#include <zephyr/kernel.h>
#include <zephyr/logging/log.h>

#include "dmic.h"

LOG_MODULE_REGISTER(dmic);

#define BLOCK_SIZE (DMIC_SAMPLE_BYTES * DMIC_SAMPLES_IN_BLOCK)
#define BLOCK_COUNT DT_PROP(DT_NODELABEL(dmic_dev), queue_size)

K_MEM_SLAB_DEFINE_STATIC(dmic_mem_slab, BLOCK_SIZE, BLOCK_COUNT, 4);

int dmic_init(void)
{
	int err;
	const struct device *const dmic_dev = DEVICE_DT_GET(DT_NODELABEL(dmic_dev));

	if (!device_is_ready(dmic_dev)) {
		LOG_ERR("Device is not ready");
		return -ENODEV;
	}

	struct pcm_stream_cfg stream = {
		.pcm_rate = DMIC_PCM_RATE,
		.pcm_width = DMIC_SAMPLE_BYTES * 8,
		.block_size = BLOCK_SIZE,
		.mem_slab = &dmic_mem_slab,
	};
	struct dmic_cfg cfg = {
		.io = {
			.min_pdm_clk_freq = 1000000,
			.max_pdm_clk_freq = 3250000,
			.min_pdm_clk_dc = 40,
			.max_pdm_clk_dc = 60,
		},
		.streams = &stream,
		.channel = {
			.req_chan_map_lo = dmic_build_channel_map(0, 0, PDM_CHAN_LEFT),
			.req_chan_map_hi = 0,
			.req_num_chan = 1,
			.req_num_streams = 1,
		},
	};

	err = dmic_configure(dmic_dev, &cfg);
	if (err < 0) {
		LOG_ERR("Failed to configure (err %d)", err);
		return err;
	}

	return 0;
}

void free_dmic_buffer(void *buffer)
{
	k_mem_slab_free(&dmic_mem_slab, buffer);
}
```

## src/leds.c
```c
/*
 * Copyright (c) 2026 Nordic Semiconductor ASA
 *
 * SPDX-License-Identifier: LicenseRef-Nordic-5-Clause
 */

#include <zephyr/devicetree.h>
#include <zephyr/drivers/gpio.h>
#include <zephyr/kernel.h>
#include <zephyr/logging/log.h>

LOG_MODULE_REGISTER(leds);

static const struct gpio_dt_spec led0 = GPIO_DT_SPEC_GET(DT_ALIAS(led0), gpios);
static const struct gpio_dt_spec led1 = GPIO_DT_SPEC_GET(DT_ALIAS(led1), gpios);
static const struct gpio_dt_spec led2 = GPIO_DT_SPEC_GET(DT_ALIAS(led2), gpios);

static void led_timer_expiry(struct k_timer *timer);
static K_TIMER_DEFINE(led_timer, led_timer_expiry, NULL);

static int led_init(const struct gpio_dt_spec *spec)
{
	int err;

	if (!gpio_is_ready_dt(spec)) {
		LOG_ERR("GPIO %s is not ready", spec->port->name);
		return -ENODEV;
	}

	err = gpio_pin_configure_dt(spec, GPIO_OUTPUT_INACTIVE);
	if (err) {
		LOG_ERR("Failed to configure GPIO %s pin %u (err %d)", spec->port->name, spec->pin,
			err);
		return err;
	}

	return 0;
}

int leds_init(void)
{
	int err;

	err = led_init(&led0);
	if (err) {
		return err;
	}

	err = led_init(&led1);
	if (err) {
		return err;
	}

	err = led_init(&led2);
	if (err) {
		return err;
	}

	return 0;
}

void leds_blink_led0(void)
{
	gpio_pin_set_dt(&led0, 1);
	k_timer_user_data_set(&led_timer, (void *)&led0);
	k_timer_start(&led_timer, K_SECONDS(1), K_NO_WAIT);
}

void leds_blink_led1(void)
{
	gpio_pin_set_dt(&led1, 1);
	k_timer_user_data_set(&led_timer, (void *)&led1);
	k_timer_start(&led_timer, K_SECONDS(1), K_NO_WAIT);
}

static void led_timer_expiry(struct k_timer *timer)
{
	const struct gpio_dt_spec *led = k_timer_user_data_get(timer);

	gpio_pin_set_dt(led, 0);
}

void leds_on_led0(void)
{
	gpio_pin_set_dt(&led0, 1);
}

void leds_off_led0(void)
{
	gpio_pin_set_dt(&led0, 0);
}

void leds_on_led1(void)
{
	gpio_pin_set_dt(&led1, 1);
}

void leds_off_led1(void)
{
	gpio_pin_set_dt(&led1, 0);
}

void leds_on_led2(void)
{
	gpio_pin_set_dt(&led2, 1);
}

void leds_off_led2(void)
{
	gpio_pin_set_dt(&led2, 0);
}
```

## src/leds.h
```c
/*
 * Copyright (c) 2026 Nordic Semiconductor ASA
 *
 * SPDX-License-Identifier: LicenseRef-Nordic-5-Clause
 */

/**
 * @defgroup leds LEDs control functions
 * @{
 * @ingroup ww_kws
 */

#ifndef __LEDS_H__
#define __LEDS_H__

#ifdef __cplusplus
extern "C" {
#endif /* __cplusplus */

/**
 * @brief Initialize LEDs.
 *
 * @return Operation status, 0 for success.
 */
int leds_init(void);

/**
 * @brief Blink with LED0.
 */
void leds_blink_led0(void);

/**
 * @brief Blink with LED1.
 */
void leds_blink_led1(void);

/**
 * @brief Turn on LED0.
 */
void leds_on_led0(void);

/**
 * @brief Turn off LED0.
 */
void leds_off_led0(void);

/**
 * @brief Turn on LED1.
 */
void leds_on_led1(void);

/**
 * @brief Turn off LED1.
 */
void leds_off_led1(void);

/**
 * @brief Turn on LED2.
 */
void leds_on_led2(void);

/**
 * @brief Turn off LED2.
 */
void leds_off_led2(void);

#ifdef __cplusplus
}
#endif /* __cplusplus */

#endif /* __LEDS_H__ */

/**
 * @}
 */
```

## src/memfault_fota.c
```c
/*
 * Copyright (c) 2026 Nordic Semiconductor ASA
 *
 * SPDX-License-Identifier: LicenseRef-Nordic-5-Clause
 */

#include <errno.h>
#include <string.h>

#include <hw_id.h>
#include <zephyr/logging/log.h>
#include <zephyr/settings/settings.h>

#include "memfault_fota.h"

LOG_MODULE_REGISTER(memfault_fota, CONFIG_LOG_DEFAULT_LEVEL);

#define SERIAL_NUMBER_SETTING_KEY "bt/dis/serial"

int memfault_fota_init(void)
{
	char serial_buf[HW_ID_LEN + 1];
	ssize_t serial_len;
	int err;

	serial_len =
		settings_load_one(SERIAL_NUMBER_SETTING_KEY, serial_buf, sizeof(serial_buf) - 1);
	if (serial_len > 0) {
		serial_buf[serial_len] = '\0';
		LOG_INF("Bluetooth DIS serial loaded from settings: %s", serial_buf);
		return 0;
	}

	err = hw_id_get(serial_buf, sizeof(serial_buf));
	if (err != 0) {
		LOG_ERR("Failed to read hardware ID for DIS serial (err %d)", err);
		return err;
	}

	serial_len = (ssize_t)strlen(serial_buf);
	err = settings_save_one(SERIAL_NUMBER_SETTING_KEY, serial_buf, (size_t)serial_len);
	if (err != 0) {
		LOG_ERR("Failed to persist DIS serial (err %d)", err);
		return err;
	}

	err = settings_runtime_set(SERIAL_NUMBER_SETTING_KEY, serial_buf, (size_t)serial_len);
	if (err != 0) {
		LOG_ERR("Failed to apply DIS serial at runtime (err %d)", err);
		return err;
	}

	LOG_INF("Bluetooth DIS serial set from hardware ID: %s", serial_buf);

	return 0;
}
```

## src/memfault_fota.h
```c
/*
 * Copyright (c) 2026 Nordic Semiconductor ASA
 *
 * SPDX-License-Identifier: LicenseRef-Nordic-5-Clause
 */

#ifndef MEMFAULT_FOTA_H_
#define MEMFAULT_FOTA_H_

#include <zephyr/sys/util.h>

/**
 * @{
 * @ingroup ww_kws
 */

#if IS_ENABLED(CONFIG_WW_KWS_MEMFAULT_FOTA)

/**
 * @brief Populate the Bluetooth DIS serial number from the hardware ID.
 *
 * Call this function after settings_load().
 *
 * @return 0 on success, -errno on failure.
 */
int memfault_fota_init(void);

#else

static inline int memfault_fota_init(void)
{
	return 0;
}

#endif /* IS_ENABLED(CONFIG_WW_KWS_MEMFAULT_FOTA) */

/**
 * @}
 */

#endif /* MEMFAULT_FOTA_H_ */
```

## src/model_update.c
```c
/*
 * Copyright (c) 2026 Nordic Semiconductor ASA
 *
 * SPDX-License-Identifier: LicenseRef-Nordic-5-Clause
 */

#include <model_ota/model_ota_smp.h>

#include <zephyr/logging/log.h>

#include "model_update.h"
#include "leds.h"

LOG_MODULE_REGISTER(model_update);

static void model_update_upload_notify(bool active)
{
	if (active) {
		leds_off_led2();
		leds_on_led1();
		return;
	}

	if (model_ota_smp_is_pending_reset()) {
		leds_off_led1();
		leds_on_led2();
	}
}

int model_update_init(void)
{
	model_ota_smp_set_upload_notify_cb(model_update_upload_notify);

	return 0;
}

bool model_update_is_pending_reset(void)
{
	return model_ota_smp_is_pending_reset();
}
```

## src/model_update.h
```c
/*
 * Copyright (c) 2026 Nordic Semiconductor ASA
 *
 * SPDX-License-Identifier: LicenseRef-Nordic-5-Clause
 */

#ifndef MODEL_UPDATE_H_
#define MODEL_UPDATE_H_

#include <stdbool.h>

int model_update_init(void);

bool model_update_is_pending_reset(void);

#endif /* MODEL_UPDATE_H_ */
```

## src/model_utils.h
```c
/*
 * Copyright (c) 2026 Nordic Semiconductor ASA
 *
 * SPDX-License-Identifier: LicenseRef-Nordic-5-Clause
 */

#ifndef MODEL_UTILS_H_
#define MODEL_UTILS_H_

/**
 * @{
 * @ingroup ww_kws
 */

#include <errno.h>
#include <stdlib.h>

#include <zephyr/sys/__assert.h>

#include <nrf_edgeai/nrf_edgeai.h>
#include <nrf_edgeai_obsv/nrf_edgeai_obsv_core.h>

/**
 * @brief Fill observability model metadata from an nRF Edge AI model instance.
 *
 * @param model       Initialized model instance.
 * @param num_classes Expected number of output classes.
 * @param info        Output metadata for nrf_edgeai_obsv_init().
 * @retval 0 Success.
 * @retval -EINVAL Solution ID is out of range for uint32_t model_id.
 */
static inline int obsv_model_info_from_model(nrf_edgeai_t *model, uint16_t num_classes,
					     nrf_edgeai_obsv_model_info_t *info)
{
	__ASSERT_NO_MSG(model != NULL);
	__ASSERT_NO_MSG(info != NULL);
	__ASSERT_NO_MSG(nrf_edgeai_model_outputs_num(model) == num_classes);

	errno = 0;
	const unsigned long model_id = strtoul(model->metadata.p_solution_id, NULL, 10);

	/* strtoul() sets ERANGE for any solution ID above UINT32_MAX.*/
	if (errno == ERANGE) {
		return -EINVAL;
	}

	const nrf_edgeai_dsp_feature_extraction_t *features_ctx =
		nrf_edgeai_dsp_features_ctx(model);

	info->model_id = (uint32_t)model_id;
	info->num_classes = num_classes;
	info->num_features = features_ctx != NULL ? features_ctx->overall_num : 0;
	info->version = model->metadata.version.combined;

	return 0;
}

/**
 * @}
 */

#endif /* MODEL_UTILS_H_ */
```

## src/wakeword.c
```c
/*
 * Copyright (c) 2026 Nordic Semiconductor ASA
 *
 * SPDX-License-Identifier: LicenseRef-Nordic-5-Clause
 */

#include <stddef.h>
#include <stdint.h>

#include <zephyr/logging/log.h>
#include <nrf_edgeai/nrf_edgeai.h>

#include "dmic.h"
#include "wakeword.h"
#include "nrf_edgeai_generated/nrf_edgeai_user_model.h"

LOG_MODULE_REGISTER(ww);

static nrf_edgeai_t *ww_model;

int ww_init(void)
{
	ww_model = nrf_edgeai_user_model_wakeword();
	__ASSERT_NO_MSG(ww_model);

	nrf_edgeai_err_t err = nrf_edgeai_init(ww_model);

	if (err) {
		LOG_ERR("Model initialization failed (err %d)", err);
		return -ENOENT;
	}

	return 0;
}

static bool ww_postprocess(void)
{
	static uint32_t ww_count;
	static uint32_t ww_history;

	const float ww_threshold = CONFIG_WW_PROBABILITY_THRESHOLD / 1000.f;

	const uint16_t predicted_class = ww_model->decoded_output.classif.predicted_class;
	const float class_probability =
		ww_model->decoded_output.classif.probabilities.p_f32[predicted_class];
	const bool ww_detected = class_probability > ww_threshold;

	const bool oldest_entry = (bool)(ww_history & BIT(CONFIG_WW_HISTORY_SIZE - 1));

	ww_count = ww_count + ww_detected - oldest_entry;
	ww_history = (ww_history << 1) | ww_detected;

	LOG_DBG("postprocess: count: %2u, probability: %f", ww_count, (double)class_probability);

	if (ww_count >= CONFIG_WW_COUNT_THRESHOLD) {
		ww_count = 0;
		ww_history = 0;

		return true;
	}

	return false;
}

int ww_process(uint8_t *const audio_buffer, const uint16_t num_samples, bool *const ww_detected)
{
	__ASSERT_NO_MSG(audio_buffer);
	__ASSERT_NO_MSG(num_samples == nrf_edgeai_input_window_size(ww_model));
	__ASSERT_NO_MSG(ww_detected);

	nrf_edgeai_err_t err;

	err = nrf_edgeai_feed_inputs(ww_model, audio_buffer, num_samples);
	free_dmic_buffer(audio_buffer);

	if (err == NRF_EDGEAI_ERR_INPROGRESS) {
		/* Skip inference, not enough data. */
		return -EBUSY;
	} else if (err) {
		LOG_ERR("Failed to feed inputs (err %d)", err);
		return -EPERM;
	}

	err = nrf_edgeai_run_inference(ww_model);
	if (err == NRF_EDGEAI_ERR_INPROGRESS) {
		/* Skip output extraction, not enough data. */
		return -EBUSY;
	} else if (err) {
		LOG_ERR("Failed to run inference (err %d)", err);
		return -EPERM;
	}

	*ww_detected = ww_postprocess();

	return 0;
}
```
